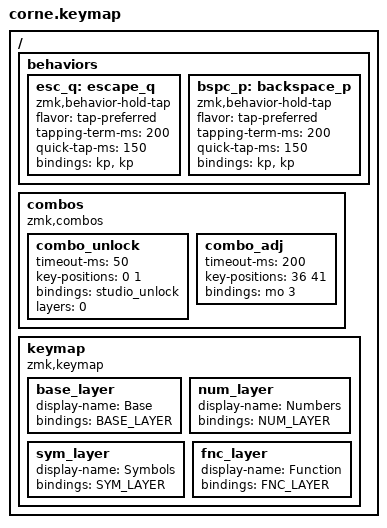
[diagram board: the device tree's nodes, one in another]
/*
 * Corne Keymap - Using Generic 3x5 Layout with 3 thumb keys
 * 
 * This keymap automatically uses the shared generic_3x5_layers.dtsi
 */

#include <behaviors.dtsi>
#include <dt-bindings/zmk/bt.h>
#include <dt-bindings/zmk/ext_power.h>
#include <dt-bindings/zmk/keys.h>
#include <dt-bindings/zmk/outputs.h>

// Include the shared behaviors and macros FIRST
#include "generic_3x5_behaviors.dtsi"

// Include the shared layer definitions (3x5 for Kaz)
#include "generic_3x5_layers.dtsi"


/ {
    behaviors {
        esc_q: escape_q {
            compatible = "zmk,behavior-hold-tap";
            #binding-cells = <2>;
            flavor = "tap-preferred";
            tapping-term-ms = <200>;
            quick-tap-ms = <150>;
            bindings = <&kp>, <&kp>;
        };
        
        bspc_p: backspace_p {
            compatible = "zmk,behavior-hold-tap";
            #binding-cells = <2>;
            flavor = "tap-preferred";
            tapping-term-ms = <200>;
            quick-tap-ms = <150>;
            bindings = <&kp>, <&kp>;
        };
    };

    combos {
        compatible = "zmk,combos";

        combo_unlock {
            timeout-ms = <50>;
            key-positions = <0 1>;
            bindings = <&studio_unlock>;
            layers = <0>;
        };

        combo_adj {
            timeout-ms = <200>;
            key-positions = <36 41>;  // Both inner thumbs for 3x6
            bindings = <&mo 3>;
        };
    };

    keymap {
        compatible = "zmk,keymap";

        base_layer {
            display-name = "Base";
            bindings = <
                BASE_LAYER
            >;
        };

        num_layer {
            display-name = "Numbers";
            bindings = <
                NUM_LAYER
            >;
        };

        sym_layer {
            display-name = "Symbols";
            bindings = <
                SYM_LAYER
            >;
        };

        fnc_layer {
            display-name = "Function";
            bindings = <
                FNC_LAYER
            >;
        };
    };
};
